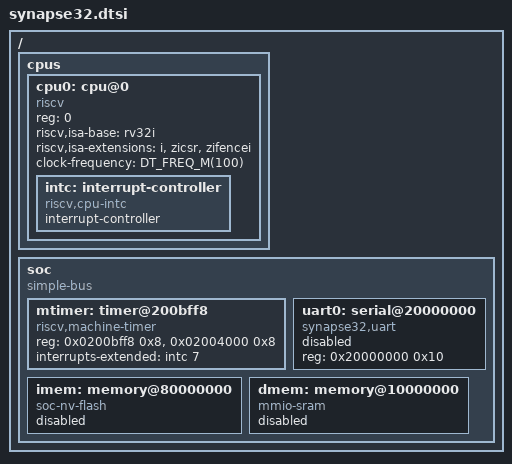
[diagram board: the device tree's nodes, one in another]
/dts-v1/;

#include <mem.h>
#include <freq.h>
#include <skeleton.dtsi>

/ {
	#address-cells = <1>;
	#size-cells = <1>;

	cpus {
		#address-cells = <1>;
		#size-cells = <0>;

		cpu0: cpu@0 {
			compatible = "riscv";
			reg = <0>;
			device_type = "cpu";
			riscv,isa-base = "rv32i";
			riscv,isa-extensions = "i", "zicsr", "zifencei";
			clock-frequency = <DT_FREQ_M(100)>;

			intc: interrupt-controller {
				compatible = "riscv,cpu-intc";
				interrupt-controller;
				#address-cells = <0>;
				#interrupt-cells = <1>;
			};
		};
	};

	soc {
		compatible = "simple-bus";
		#address-cells = <1>;
		#size-cells = <1>;
		ranges;

		mtimer: timer@200bff8 {
			compatible = "riscv,machine-timer";
			reg = <0x0200bff8 0x8>, <0x02004000 0x8>;
			reg-names = "mtime", "mtimecmp";
			interrupts-extended = <&intc 7>;
			status = "okay";
		};

		uart0: serial@20000000 {
			compatible = "synapse32,uart";
			reg = <0x20000000 0x10>;
			status = "disabled";
		};

		imem: memory@80000000 {
			compatible = "soc-nv-flash", "mmio-sram";
			status = "disabled";
		};

		dmem: memory@10000000 {
			compatible = "mmio-sram";
			status = "disabled";
		};
	};
};
